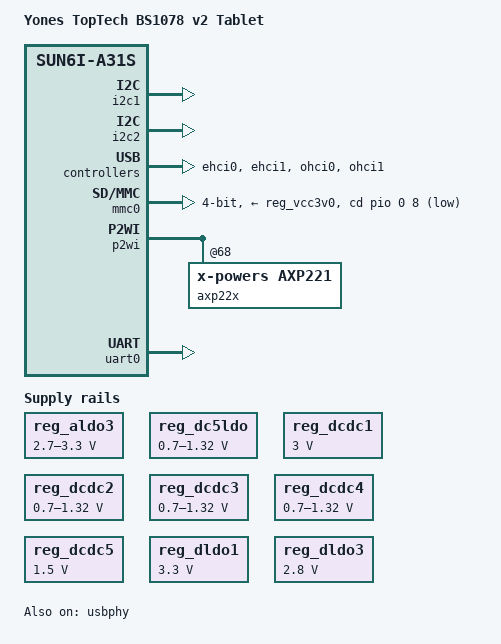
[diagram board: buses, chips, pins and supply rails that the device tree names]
/dts-v1/;
#include "sun6i-a31s.dtsi"
#include "sunxi-common-regulators.dtsi"
#include <dt-bindings/gpio/gpio.h>
/ {
	model = "Yones TopTech BS1078 v2 Tablet";
	compatible = "yones-toptech,bs1078-v2", "allwinner,sun6i-a31s";
	aliases {
		serial0 = &uart0;
		i2c1 = &i2c1;
		i2c2 = &i2c2;
	};
	chosen {
		stdout-path = "serial0:115200n8";
	};
};
&i2c1 {
	status = "okay";
};
&i2c2 {
	status = "okay";
};
&ehci0 {
	status = "okay";
};
&ehci1 {
	status = "okay";
};
&ohci0 {
	status = "okay";
};
&ohci1 {
	status = "okay";
};
&mmc0 {
	vmmc-supply = <&reg_vcc3v0>;
	bus-width = <4>;
	cd-gpios = <&pio 0 8 GPIO_ACTIVE_LOW>;  
	status = "okay";
};
&p2wi {
	status = "okay";
	axp22x: pmic@68 {
		compatible = "x-powers,axp221";
		reg = <0x68>;
		interrupt-parent = <&r_intc>;
		interrupts = <GIC_SPI 32 IRQ_TYPE_LEVEL_LOW>;
	};
};
#include "axp22x.dtsi"
&reg_aldo3 {
	regulator-always-on;
	regulator-min-microvolt = <2700000>;
	regulator-max-microvolt = <3300000>;
	regulator-name = "avcc";
};
&reg_dc1sw {
	regulator-name = "vcc-lcd-usb2";
};
&reg_dc5ldo {
	regulator-min-microvolt = <700000>;
	regulator-max-microvolt = <1320000>;
	regulator-name = "vdd-cpus";
};
&reg_dcdc1 {
	regulator-always-on;
	regulator-min-microvolt = <3000000>;
	regulator-max-microvolt = <3000000>;
	regulator-name = "vcc-3v0";
};
&reg_dcdc2 {
	regulator-min-microvolt = <700000>;
	regulator-max-microvolt = <1320000>;
	regulator-name = "vdd-gpu";
};
&reg_dcdc3 {
	regulator-always-on;
	regulator-min-microvolt = <700000>;
	regulator-max-microvolt = <1320000>;
	regulator-name = "vdd-cpu";
};
&reg_dcdc4 {
	regulator-always-on;
	regulator-min-microvolt = <700000>;
	regulator-max-microvolt = <1320000>;
	regulator-name = "vdd-sys-dll";
};
&reg_dcdc5 {
	regulator-always-on;
	regulator-min-microvolt = <1500000>;
	regulator-max-microvolt = <1500000>;
	regulator-name = "vcc-dram";
};
&reg_dldo1 {
	regulator-min-microvolt = <3300000>;
	regulator-max-microvolt = <3300000>;
	regulator-name = "vcc-wifi";
};
&reg_dldo3 {
	regulator-min-microvolt = <2800000>;
	regulator-max-microvolt = <2800000>;
	regulator-name = "vddio-csi";
};
&uart0 {
	pinctrl-names = "default";
	pinctrl-0 = <&uart0_ph_pins>;
	status = "okay";
};
&usbphy {
	usb1_vbus-supply = <&reg_dldo1>;
	usb2_vbus-supply = <&reg_dc1sw>;
	status = "okay";
};
